# SIM3L164_C register map
File version: 1
CPU: 
Registers are 32-bit, read-write, reset 0x0 unless marked. A register's access mark holds for its fields unless they carry their own. Offsets are from the block's base; [hi:lo] are bit positions; <NAME> marks a mode.

## CMP_0
Base 0x4001F000
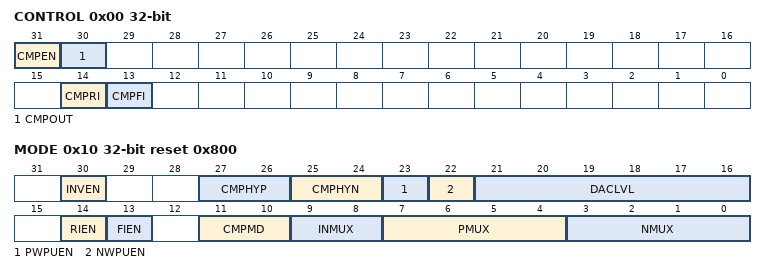
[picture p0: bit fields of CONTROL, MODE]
0x00 CONTROL — Module Control
  [31] CMPEN — Comparator Enable.
    0=DISABLED (Disable the comparator.); 1=ENABLED (Enable the comparator.)
  [30] CMPOUT ro — Output State.
    0=POS_LT_NEG (Voltage on CMP+ < CMP- (INVEN = 0).); 1=POS_GT_NEG (Voltage on CMP+ > CMP- (INVEN = 0).)
  [14] CMPRI — Rising Edge Interrupt Flag.
    0=NOT_SET (No comparator rising edge has occurred since this flag was last cleared.); 1=SET (A comparator rising edge occurred since last flag was cleared.)
  [13] CMPFI — Falling Edge Interrupt Flag.
    0=NOT_SET (No comparator falling edge has occurred since this flag was last cleared.); 1=SET (A comparator falling edge occurred since last flag was cleared.)
0x10 MODE reset 0x800 — Input and Module Mode
  [30] INVEN — Invert Comparator Output Enable.
    0=DISABLED (Do not invert the comparator output.); 1=ENABLED (Invert the comparator output.)
  [27:26] CMPHYP — Positive Hysteresis Control.
    0=DISABLED (Disable positive hysteresis.); 1=POS_5_MV (Set positive hysteresis to 5 mV.); 2=POS_10_MV (Set positive hysteresis to 10 mV.); 3=POS_20_MV (Set positive hysteresis to 20 mV.)
  [25:24] CMPHYN — Negative Hysteresis Control.
    0=DISABLED (Disable negative hysteresis.); 1=NEG_5_MV (Set negative hysteresis to 5 mV.); 2=NEG_10_MV (Set negative hysteresis to 10 mV.); 3=NEG_20_MV (Set negative hysteresis to 20 mV.)
  [23] PWPUEN — Positive Input Weak Pullup Enable.
    0=DISABLED (Disable the positive input weak pull up.); 1=ENABLED (Enable the positive input weak pull up.)
  [22] NWPUEN — Negative Input Weak Pullup Enable.
    0=DISABLED (Disable the negative input weak pull up.); 1=ENABLED (Enable the negative input weak pull up.)
  [21:16] DACLVL — Comparator DAC Output Level.
  [14] RIEN — Rising Edge Interrupt Enable.
    0=DISABLED (Disable the comparator rising edge interrupt.); 1=ENABLED (Enable the comparator rising edge interrupt.)
  [13] FIEN — Falling Edge Interrupt Enable.
    0=DISABLED (Disable the comparator falling edge interrupt.); 1=ENABLED (Enable the comparator falling edge interrupt.)
  [11:10] CMPMD — Comparator Mode.
    0=MODE0 (Mode 0 (fastest response time, highest power consumption).); 1=MODE1; 2=MODE2; 3=MODE3 (Mode 3 (slowest response time, lowest power consumption).)
  [9:8] INMUX — Input MUX Select.
    0=DIRECT (Connects the NMUX signal to CMP- and the PMUX signal to CMP+.); 1=CMPP_VSS (Connects VSS to CMP- and the PMUX signal to CMP+.); 2=CMPP_DAC (Connects the NMUX signal to CMP-, the PMUX signal to the Comparator DAC voltage reference, and the DAC output to CMP+.); 3=CMPN_DAC (Connects the PMUX signal to CMP+, the NMUX signal to the Comparator DAC voltage reference, and the DAC output to CMP-.)
  [7:4] PMUX — Positive Input Select.
    0=CMPNP0 (Select CMPnP.0 (PB0.0).); 1=CMPNP1 (Select CMPnP.1 (PB0.3).); 2=CMPNP2 (Select CMPnP.2 (RESERVED).); 3=CMPNP3 (Select CMPnP.3 (RESERVED).); 4=CMPNP4 (Select CMPnP.4 (PB2.0).); 5=CMPNP5 (Select CMPnP.5 (PB2.4).); 6=CMPNP6 (Select CMPnP.6 (RESERVED).); 7=CMPNP7 (Select CMPnP.7 (RESERVED).); 8=CMPNP8 (Select CMPnP.8 (VREF Pin).); 9=CMPNP9 (Select CMPnP.9 (RESERVED).); 10=CMPNP10 (Select CMPnP.10 (Temperature Sensor Output).); 11=CMPNP11 (Select CMPnP.11 (Charge Pump / 2).); 12=CMPNP12 (Select CMPnP.12 (Digital LDO Output).); 13=CMPNP13 (Select CMPnP.13 (Memory LDO Output).); 14=CMPNP14 (Select CMPnP.14 (Analog LDO Output).); 15=CMPNP15 (Select CMPnP.15 (RESERVED).)
  [3:0] NMUX — Negative Input Select.
    0=CMPNN0 (Select CMPnN.0 (PB0.1).); 1=CMPNN1 (Select CMPnN.1 (PB0.2).); 2=CMPNN2 (Select CMPnN.2 (RESERVED).); 3=CMPNN3 (Select CMPnN.3 (RESERVED).); 4=CMPNN4 (Select CMPnN.4 (PB2.1).); 5=CMPNN5 (Select CMPnN.5 (PB2.5).); 6=CMPNN6 (Select CMPnN.6 (RESERVED).); 7=CMPNN7 (Select CMPnN.7 (PB3.0).); 8=CMPNN8 (Select CMPnN.8 (VREF Pin).); 9=CMPNN9 (Select CMPnN.9 (VBAT).); 10=CMPNN10 (Select CMPnN.10 (VDC).); 11=CMPNN11 (Select CMPnN.11 (Digital LDO Output).); 12=CMPNN12 (Select CMPnN.12 (Memory LDO Output).); 13=CMPNN13 (Select CMPnN.13 (Analog LDO Output).); 14=CMPNN14 (Select CMPnN.14 (VIO).); 15=CMPNN15 (Select CMPnN.15 (RESERVED).)
